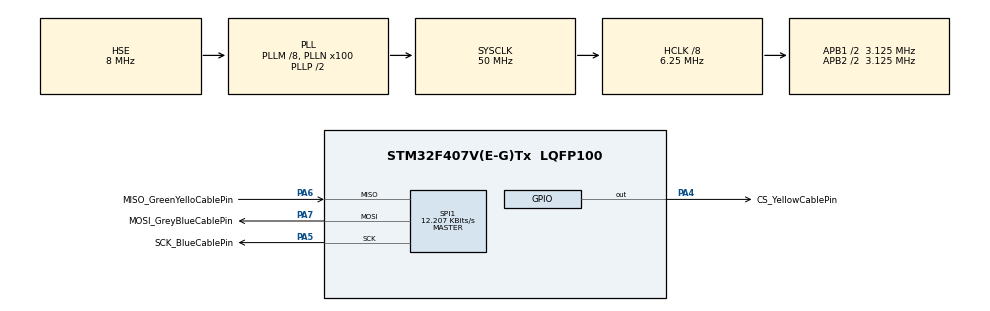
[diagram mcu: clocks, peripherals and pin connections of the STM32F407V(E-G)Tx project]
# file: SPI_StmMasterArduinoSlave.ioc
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Dma.Request0=SPI1_RX
Dma.Request1=SPI1_TX
Dma.SPI1_RX.0.Direction=DMA_PERIPH_TO_MEMORY
Dma.SPI1_RX.0.FIFOMode=DMA_FIFOMODE_DISABLE
Dma.SPI1_RX.0.Instance=DMA2_Stream0
Dma.SPI1_RX.0.MemDataAlignment=DMA_MDATAALIGN_BYTE
Dma.SPI1_RX.0.MemInc=DMA_MINC_ENABLE
Dma.SPI1_RX.0.Mode=DMA_NORMAL
Dma.SPI1_RX.0.PeriphDataAlignment=DMA_PDATAALIGN_BYTE
Dma.SPI1_RX.0.PeriphInc=DMA_PINC_DISABLE
Dma.SPI1_RX.0.Priority=DMA_PRIORITY_LOW
Dma.SPI1_TX.1.Direction=DMA_MEMORY_TO_PERIPH
Dma.SPI1_TX.1.FIFOMode=DMA_FIFOMODE_DISABLE
Dma.SPI1_TX.1.Instance=DMA2_Stream3
Dma.SPI1_TX.1.MemDataAlignment=DMA_MDATAALIGN_BYTE
Dma.SPI1_TX.1.MemInc=DMA_MINC_ENABLE
Dma.SPI1_TX.1.Mode=DMA_NORMAL
Dma.SPI1_TX.1.PeriphDataAlignment=DMA_PDATAALIGN_BYTE
Dma.SPI1_TX.1.PeriphInc=DMA_PINC_DISABLE
Dma.SPI1_TX.1.Priority=DMA_PRIORITY_LOW
Mcu.Family=STM32F4
Mcu.Name=STM32F407V(E-G)Tx
Mcu.Package=LQFP100
NVIC.DMA2_Stream0_IRQn=true\:0\:0\:false\:false\:true\:false\:true
NVIC.DMA2_Stream3_IRQn=true\:0\:0\:false\:false\:true\:false\:true
NVIC.PriorityGroup=NVIC_PRIORITYGROUP_0
NVIC.SPI1_IRQn=true\:0\:0\:false\:false\:true\:true\:true
PA10.GPIO_Label=OTG_FS_ID
PA10.GPIO_Mode=GPIO_MODE_AF_PP
PA10.GPIO_PuPd=GPIO_NOPULL
PA10.GPIO_Speed=GPIO_SPEED_FREQ_LOW
PA10.Signal=USB_OTG_FS_ID
PA11.GPIO_Label=OTG_FS_DM
PA11.GPIO_Mode=GPIO_MODE_AF_PP
PA11.GPIO_PuPd=GPIO_NOPULL
PA11.GPIO_Speed=GPIO_SPEED_FREQ_LOW
PA11.Signal=USB_OTG_FS_DM
PA12.GPIO_Label=OTG_FS_DP
PA12.GPIO_Mode=GPIO_MODE_AF_PP
PA12.GPIO_PuPd=GPIO_NOPULL
PA12.GPIO_Speed=GPIO_SPEED_FREQ_LOW
PA12.Signal=USB_OTG_FS_DP
PA13.GPIO_Label=SWDIO
PA13.Signal=SYS_JTMS-SWDIO
PA14.GPIO_Label=SWCLK
PA14.Signal=SYS_JTCK-SWCLK
PA4.GPIO_Label=CS_YellowCablePin
PA4.Signal=GPIO_Output
PA5.GPIO_Label=SCK_BlueCablePin
PA5.Mode=Full_Duplex_Master
PA5.Signal=SPI1_SCK
PA6.GPIO_Label=MISO_GreenYelloCablePin
PA6.Mode=Full_Duplex_Master
PA6.Signal=SPI1_MISO
PA7.GPIO_Label=MOSI_GreyBlueCablePin
PA7.Mode=Full_Duplex_Master
PA7.Signal=SPI1_MOSI
PA9.GPIO_Label=VBUS_FS
PA9.GPIO_Mode=GPIO_MODE_INPUT
PA9.GPIO_PuPd=GPIO_NOPULL
PA9.Signal=USB_OTG_FS_VBUS
PB10.GPIO_Label=CLK_IN [MP45DT02_CLK]
PB10.GPIO_Mode=GPIO_MODE_AF_PP
PB10.GPIO_PuPd=GPIO_NOPULL
PB10.GPIO_Speed=GPIO_SPEED_FREQ_LOW
PB10.Signal=I2S2_CK
PB3.GPIO_Label=SWO
PB3.Signal=SYS_JTDO-SWO
PB6.GPIO_Label=Audio_SCL [CS43L22_SCL]
PB6.GPIO_Mode=GPIO_MODE_AF_OD
PB6.GPIO_PuPd=GPIO_NOPULL
PB6.GPIO_Speed=GPIO_SPEED_FREQ_LOW
PB6.Signal=I2C1_SCL
PB9.GPIO_Label=Audio_SDA [CS43L22_SDA]
PB9.GPIO_Mode=GPIO_MODE_AF_OD
PB9.GPIO_PuPd=GPIO_NOPULL
PB9.GPIO_Speed=GPIO_SPEED_FREQ_LOW
PB9.Signal=I2C1_SDA
PC10.GPIO_Label=I2S3_SCK [CS43L22_SCLK]
PC10.GPIO_Mode=GPIO_MODE_AF_PP
PC10.GPIO_PuPd=GPIO_NOPULL
PC10.GPIO_Speed=GPIO_SPEED_FREQ_LOW
PC10.Signal=I2S3_CK
PC12.GPIO_Label=I2S3_SD [CS43L22_SDIN]
PC12.GPIO_Mode=GPIO_MODE_AF_PP
PC12.GPIO_PuPd=GPIO_NOPULL
PC12.GPIO_Speed=GPIO_SPEED_FREQ_LOW
PC12.Signal=I2S3_SD
PC14-OSC32_IN.GPIO_Label=PC14-OSC32_IN
PC14-OSC32_IN.Signal=RCC_OSC32_IN
PC15-OSC32_OUT.GPIO_Label=PC15-OSC32_OUT
PC15-OSC32_OUT.Signal=RCC_OSC32_OUT
PC3.GPIO_Label=PDM_OUT [MP45DT02_DOUT]
PC3.GPIO_Mode=GPIO_MODE_AF_PP
PC3.GPIO_PuPd=GPIO_NOPULL
PC3.GPIO_Speed=GPIO_SPEED_FREQ_LOW
PC3.Signal=I2S2_SD
PC7.GPIO_Label=I2S3_MCK [CS43L22_MCLK]
PC7.GPIO_Mode=GPIO_MODE_AF_PP
PC7.GPIO_PuPd=GPIO_NOPULL
PC7.GPIO_Speed=GPIO_SPEED_FREQ_LOW
PC7.Signal=I2S3_MCK
PH0-OSC_IN.GPIO_Label=PH0-OSC_IN
PH0-OSC_IN.Mode=HSE-External-Oscillator
PH0-OSC_IN.Signal=RCC_OSC_IN
PH1-OSC_OUT.GPIO_Label=PH1-OSC_OUT
PH1-OSC_OUT.Mode=HSE-External-Oscillator
PH1-OSC_OUT.Signal=RCC_OSC_OUT
ProjectManager.HeapSize=0x200
ProjectManager.StackSize=0x400
ProjectManager.TargetToolchain=STM32CubeIDE
RCC.48MHZClocksFreq_Value=14285714.285714285
RCC.AHBCLKDivider=RCC_SYSCLK_DIV8
RCC.AHBFreq_Value=6250000
RCC.APB1CLKDivider=RCC_HCLK_DIV2
RCC.APB1Freq_Value=3125000
RCC.APB1TimFreq_Value=6250000
RCC.APB2CLKDivider=RCC_HCLK_DIV2
RCC.APB2Freq_Value=3125000
RCC.APB2TimFreq_Value=6250000
RCC.CortexFreq_Value=6250000
RCC.HCLKFreq_Value=6250000
RCC.HSE_VALUE=8000000
RCC.HSI_VALUE=16000000
RCC.LSE_VALUE=32768
RCC.PLLM=8
RCC.PLLN=100
RCC.PLLQ=7
RCC.PLLSourceVirtual=RCC_PLLSOURCE_HSE
RCC.SYSCLKFreq_VALUE=50000000
RCC.SYSCLKSource=RCC_SYSCLKSOURCE_PLLCLK
RCC.VCOOutputFreq_Value=100000000
SPI1.BaudRatePrescaler=SPI_BAUDRATEPRESCALER_256
SPI1.CLKPolarity=SPI_POLARITY_LOW
SPI1.CRCCalculation=SPI_CRCCALCULATION_DISABLE
SPI1.CalculateBaudRate=12.207 KBits/s
SPI1.Direction=SPI_DIRECTION_2LINES
SPI1.FirstBit=SPI_FIRSTBIT_MSB
SPI1.Mode=SPI_MODE_MASTER
SPI1.VirtualType=VM_MASTER
board=STM32F407G-DISC1

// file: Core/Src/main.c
/* USER CODE BEGIN Header */
/**
  ******************************************************************************
  * @file           : main.c
  * @brief          : Main program body
  ******************************************************************************
  * @attention
  *
  * <h2><center>&copy; Copyright (c) 2020 STMicroelectronics.
  * All rights reserved.</center></h2>
  *
  * This software component is licensed by ST under BSD 3-Clause license,
  * the "License"; You may not use this file except in compliance with the
  * License. You may obtain a copy of the License at:
  *                        opensource.org/licenses/BSD-3-Clause
  *
  ******************************************************************************
  */
/* USER CODE END Header */
#include "main.h"

SPI_HandleTypeDef hspi1;
DMA_HandleTypeDef hdma_spi1_rx;
DMA_HandleTypeDef hdma_spi1_tx;

/* USER CODE BEGIN PV */
uint8_t hello_arduino[13] = {'H', 'e', 'l', 'l', 'o', ' ', 'A', 'r', 'd', 'u', 'i', 'n', 'o'};
uint8_t hello_st[8] = {'a', 'a', 'a', 'a', 'a', 'a', 'a', 'a'};
/* USER CODE END PV */

void SystemClock_Config(void);
static void MX_GPIO_Init(void);
static void MX_DMA_Init(void);
static void MX_SPI1_Init(void);

int main(void)
{

  /* MCU Configuration--------------------------------------------------------*/

  /* Reset of all peripherals, Initializes the Flash interface and the Systick. */
  HAL_Init();

  /* Configure the system clock */
  SystemClock_Config();

  /* Initialize all configured peripherals */
  MX_GPIO_Init();
  MX_DMA_Init();
  MX_SPI1_Init();

  /* Infinite loop */
  /* USER CODE BEGIN WHILE */
  while (1)
  {
	  HAL_GPIO_WritePin(CS_YellowCablePin_GPIO_Port, CS_YellowCablePin_Pin, SET);
	  HAL_Delay(1);
	  HAL_GPIO_WritePin(CS_YellowCablePin_GPIO_Port, CS_YellowCablePin_Pin, RESET);
	  HAL_Delay(1);
	  //HAL_SPI_TransmitReceive_DMA(&hspi1, hello_arduino, hello_st, 13);
	  HAL_SPI_Transmit(&hspi1, hello_arduino, 13, HAL_MAX_DELAY);
	  HAL_Delay(1);
	  HAL_SPI_Receive(&hspi1, hello_st, 8, HAL_MAX_DELAY);
	  HAL_Delay(10);
	  HAL_GPIO_WritePin(CS_YellowCablePin_GPIO_Port, CS_YellowCablePin_Pin, SET);
	  HAL_Delay(100);
    /* USER CODE END WHILE */

  }
}

void SystemClock_Config(void)
{
  RCC_OscInitTypeDef RCC_OscInitStruct = {0};
  RCC_ClkInitTypeDef RCC_ClkInitStruct = {0};

  /** Configure the main internal regulator output voltage
  */
  __HAL_RCC_PWR_CLK_ENABLE();
  __HAL_PWR_VOLTAGESCALING_CONFIG(PWR_REGULATOR_VOLTAGE_SCALE1);
  /** Initializes the RCC Oscillators according to the specified parameters
  * in the RCC_OscInitTypeDef structure.
  */
  RCC_OscInitStruct.OscillatorType = RCC_OSCILLATORTYPE_HSE;
  RCC_OscInitStruct.HSEState = RCC_HSE_ON;
  RCC_OscInitStruct.PLL.PLLState = RCC_PLL_ON;
  RCC_OscInitStruct.PLL.PLLSource = RCC_PLLSOURCE_HSE;
  RCC_OscInitStruct.PLL.PLLM = 8;
  RCC_OscInitStruct.PLL.PLLN = 100;
  RCC_OscInitStruct.PLL.PLLP = RCC_PLLP_DIV2;
  RCC_OscInitStruct.PLL.PLLQ = 7;
  if (HAL_RCC_OscConfig(&RCC_OscInitStruct) != HAL_OK)
  {
    Error_Handler();
  }
  /** Initializes the CPU, AHB and APB buses clocks
  */
  RCC_ClkInitStruct.ClockType = RCC_CLOCKTYPE_HCLK|RCC_CLOCKTYPE_SYSCLK
                              |RCC_CLOCKTYPE_PCLK1|RCC_CLOCKTYPE_PCLK2;
  RCC_ClkInitStruct.SYSCLKSource = RCC_SYSCLKSOURCE_PLLCLK;
  RCC_ClkInitStruct.AHBCLKDivider = RCC_SYSCLK_DIV8;
  RCC_ClkInitStruct.APB1CLKDivider = RCC_HCLK_DIV2;
  RCC_ClkInitStruct.APB2CLKDivider = RCC_HCLK_DIV2;

  if (HAL_RCC_ClockConfig(&RCC_ClkInitStruct, FLASH_LATENCY_0) != HAL_OK)
  {
    Error_Handler();
  }
}

static void MX_SPI1_Init(void)
{

  /* SPI1 parameter configuration*/
  hspi1.Instance = SPI1;
  hspi1.Init.Mode = SPI_MODE_MASTER;
  hspi1.Init.Direction = SPI_DIRECTION_2LINES;
  hspi1.Init.DataSize = SPI_DATASIZE_8BIT;
  hspi1.Init.CLKPolarity = SPI_POLARITY_LOW;
  hspi1.Init.CLKPhase = SPI_PHASE_1EDGE;
  hspi1.Init.NSS = SPI_NSS_SOFT;
  hspi1.Init.BaudRatePrescaler = SPI_BAUDRATEPRESCALER_256;
  hspi1.Init.FirstBit = SPI_FIRSTBIT_MSB;
  hspi1.Init.TIMode = SPI_TIMODE_DISABLE;
  hspi1.Init.CRCCalculation = SPI_CRCCALCULATION_DISABLE;
  hspi1.Init.CRCPolynomial = 10;
  if (HAL_SPI_Init(&hspi1) != HAL_OK)
  {
    Error_Handler();
  }

}

static void MX_DMA_Init(void)
{

  /* DMA controller clock enable */
  __HAL_RCC_DMA2_CLK_ENABLE();

  /* DMA interrupt init */
  /* DMA2_Stream0_IRQn interrupt configuration */
  HAL_NVIC_SetPriority(DMA2_Stream0_IRQn, 0, 0);
  HAL_NVIC_EnableIRQ(DMA2_Stream0_IRQn);
  /* DMA2_Stream3_IRQn interrupt configuration */
  HAL_NVIC_SetPriority(DMA2_Stream3_IRQn, 0, 0);
  HAL_NVIC_EnableIRQ(DMA2_Stream3_IRQn);

}

static void MX_GPIO_Init(void)
{
  GPIO_InitTypeDef GPIO_InitStruct = {0};

  /* GPIO Ports Clock Enable */
  __HAL_RCC_GPIOC_CLK_ENABLE();
  __HAL_RCC_GPIOH_CLK_ENABLE();
  __HAL_RCC_GPIOA_CLK_ENABLE();
  __HAL_RCC_GPIOB_CLK_ENABLE();

  /*Configure GPIO pin Output Level */
  HAL_GPIO_WritePin(CS_YellowCablePin_GPIO_Port, CS_YellowCablePin_Pin, GPIO_PIN_RESET);

  /*Configure GPIO pin : PDM_OUT_Pin */
  GPIO_InitStruct.Pin = PDM_OUT_Pin;
  GPIO_InitStruct.Mode = GPIO_MODE_AF_PP;
  GPIO_InitStruct.Pull = GPIO_NOPULL;
  GPIO_InitStruct.Speed = GPIO_SPEED_FREQ_LOW;
  GPIO_InitStruct.Alternate = GPIO_AF5_SPI2;
  HAL_GPIO_Init(PDM_OUT_GPIO_Port, &GPIO_InitStruct);

  /*Configure GPIO pin : CS_YellowCablePin_Pin */
  GPIO_InitStruct.Pin = CS_YellowCablePin_Pin;
  GPIO_InitStruct.Mode = GPIO_MODE_OUTPUT_PP;
  GPIO_InitStruct.Pull = GPIO_NOPULL;
  GPIO_InitStruct.Speed = GPIO_SPEED_FREQ_LOW;
  HAL_GPIO_Init(CS_YellowCablePin_GPIO_Port, &GPIO_InitStruct);

  /*Configure GPIO pin : CLK_IN_Pin */
  GPIO_InitStruct.Pin = CLK_IN_Pin;
  GPIO_InitStruct.Mode = GPIO_MODE_AF_PP;
  GPIO_InitStruct.Pull = GPIO_NOPULL;
  GPIO_InitStruct.Speed = GPIO_SPEED_FREQ_LOW;
  GPIO_InitStruct.Alternate = GPIO_AF5_SPI2;
  HAL_GPIO_Init(CLK_IN_GPIO_Port, &GPIO_InitStruct);

  /*Configure GPIO pins : I2S3_MCK_Pin I2S3_SCK_Pin I2S3_SD_Pin */
  GPIO_InitStruct.Pin = I2S3_MCK_Pin|I2S3_SCK_Pin|I2S3_SD_Pin;
  GPIO_InitStruct.Mode = GPIO_MODE_AF_PP;
  GPIO_InitStruct.Pull = GPIO_NOPULL;
  GPIO_InitStruct.Speed = GPIO_SPEED_FREQ_LOW;
  GPIO_InitStruct.Alternate = GPIO_AF6_SPI3;
  HAL_GPIO_Init(GPIOC, &GPIO_InitStruct);

  /*Configure GPIO pin : VBUS_FS_Pin */
  GPIO_InitStruct.Pin = VBUS_FS_Pin;
  GPIO_InitStruct.Mode = GPIO_MODE_INPUT;
  GPIO_InitStruct.Pull = GPIO_NOPULL;
  HAL_GPIO_Init(VBUS_FS_GPIO_Port, &GPIO_InitStruct);

  /*Configure GPIO pins : OTG_FS_ID_Pin OTG_FS_DM_Pin OTG_FS_DP_Pin */
  GPIO_InitStruct.Pin = OTG_FS_ID_Pin|OTG_FS_DM_Pin|OTG_FS_DP_Pin;
  GPIO_InitStruct.Mode = GPIO_MODE_AF_PP;
  GPIO_InitStruct.Pull = GPIO_NOPULL;
  GPIO_InitStruct.Speed = GPIO_SPEED_FREQ_LOW;
  GPIO_InitStruct.Alternate = GPIO_AF10_OTG_FS;
  HAL_GPIO_Init(GPIOA, &GPIO_InitStruct);

  /*Configure GPIO pins : Audio_SCL_Pin Audio_SDA_Pin */
  GPIO_InitStruct.Pin = Audio_SCL_Pin|Audio_SDA_Pin;
  GPIO_InitStruct.Mode = GPIO_MODE_AF_OD;
  GPIO_InitStruct.Pull = GPIO_PULLUP;
  GPIO_InitStruct.Speed = GPIO_SPEED_FREQ_LOW;
  GPIO_InitStruct.Alternate = GPIO_AF4_I2C1;
  HAL_GPIO_Init(GPIOB, &GPIO_InitStruct);

}

void Error_Handler(void)
{
}

/************************ (C) COPYRIGHT STMicroelectronics *****END OF FILE****/
